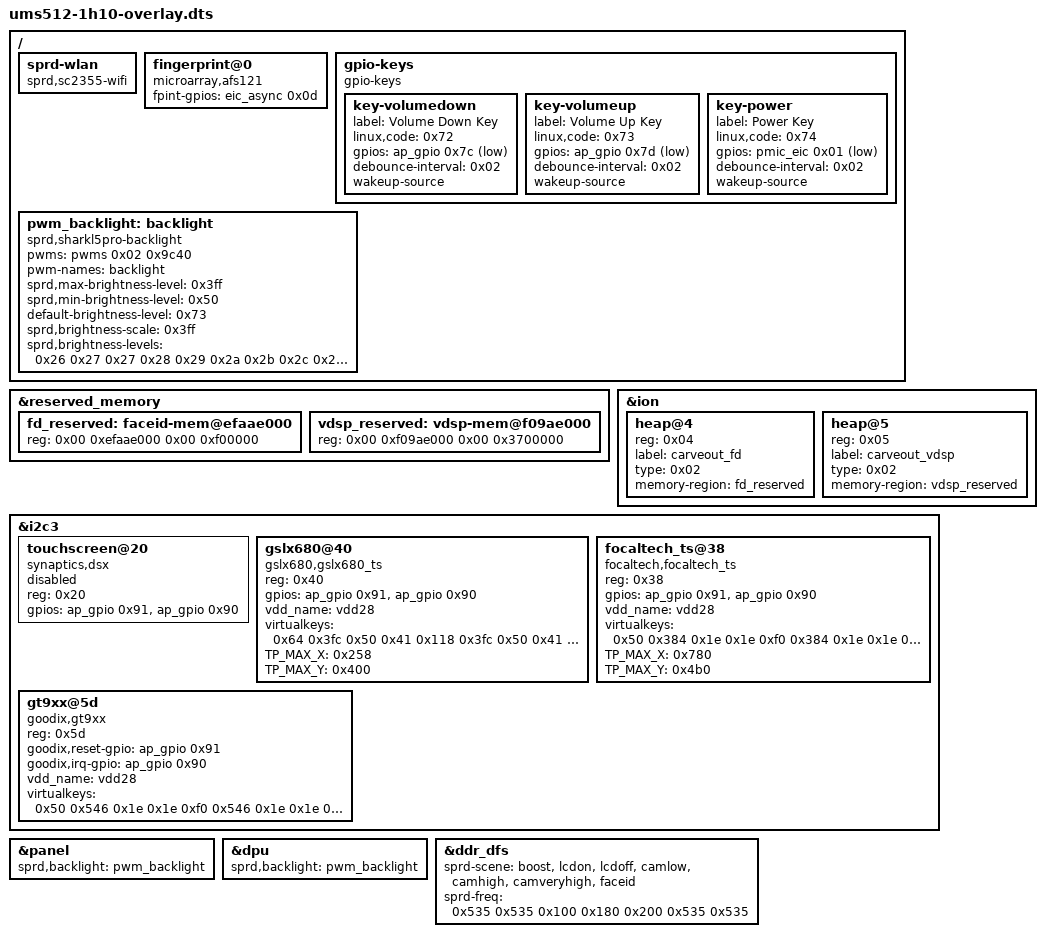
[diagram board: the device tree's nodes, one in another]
/dts-v1/;
/plugin/;

/ {
	fragment {
		target-path = "/";

		__overlay__ {
			sprd-wlan {
				compatible = "sprd,sc2355-wifi";
			};

			fingerprint@0 {
				compatible = "microarray,afs121";
				fpint-gpios = <&eic_async 0x0d 0x00>;
			};

			gpio-keys {
				compatible = "gpio-keys";

				key-volumedown {
					label = "Volume Down Key";
					linux,code = <0x72>;
					gpios = <&ap_gpio 0x7c 0x01>;
					debounce-interval = <0x02>;
					wakeup-source;
				};

				key-volumeup {
					label = "Volume Up Key";
					linux,code = <0x73>;
					gpios = <&ap_gpio 0x7d 0x01>;
					debounce-interval = <0x02>;
					wakeup-source;
				};

				key-power {
					label = "Power Key";
					linux,code = <0x74>;
					gpios = <&pmic_eic 0x01 0x01>;
					debounce-interval = <0x02>;
					wakeup-source;
				};
			};

			pwm_backlight: backlight {
				compatible = "sprd,sharkl5pro-backlight";
				pwms = <&pwms 0x02 0x9c40>;
				pwm-names = "backlight";
				sprd,max-brightness-level = <0x3ff>;
				sprd,min-brightness-level = <0x50>;
				default-brightness-level = <0x73>;
				sprd,brightness-scale = <0x3ff>;
				sprd,brightness-levels = <0x26 0x27 0x27 0x28 0x29 0x2a 0x2b 0x2c 0x2c 0x2d 0x2e 0x2f 0x30 0x31 0x31 0x32 0x33 0x34 0x35 0x36 0x36 0x37 0x38 0x39 0x3a 0x3b 0x3b 0x3c 0x3d 0x3e 0x3f 0x40 0x40 0x41 0x42 0x43 0x44 0x45 0x45 0x46 0x47 0x48 0x49 0x4a 0x4a 0x4b 0x4c 0x4d 0x4e 0x4f 0x4f 0x50 0x51 0x52 0x53 0x54 0x54 0x55 0x56 0x57 0x58 0x59 0x59 0x5a 0x5b 0x5c 0x5d 0x5e 0x5e 0x5f 0x60 0x61 0x62 0x63 0x64 0x64 0x65 0x66 0x67 0x68 0x69 0x6a 0x6a 0x6b 0x6c 0x6d 0x6e 0x6f 0x70 0x70 0x71 0x72 0x73 0x74 0x75 0x76 0x76 0x77 0x78 0x79 0x7a 0x7b 0x7c 0x7c 0x7d 0x7e 0x7f 0x80 0x81 0x82 0x82 0x83 0x84 0x85 0x86 0x87 0x88 0x88 0x89 0x8a 0x8b 0x8c 0x8d 0x8e 0x8e 0x8f 0x90 0x91 0x92 0x93 0x94 0x94 0x95 0x96 0x97 0x98 0x99 0x9a 0x9a 0x9b 0x9c 0x9d 0x9e 0x9f 0xa0 0xa0 0xa1 0xa2 0xa3 0xa4 0xa5 0xa6 0xa6 0xa7 0xa8 0xa9 0xaa 0xab 0xac 0xac 0xad 0xae 0xaf 0xb0 0xb1 0xb2 0xb2 0xb3 0xb4 0xb5 0xb6 0xb7 0xb8 0xb8 0xb9 0xba 0xbb 0xbc 0xbd 0xbe 0xbe 0xbf 0xc0 0xc1 0xc2 0xc3 0xc4 0xc4 0xc5 0xc6 0xc7 0xc8 0xc9 0xca 0xca 0xcb 0xcc 0xcd 0xce 0xcf 0xd0 0xd0 0xd1 0xd2 0xd3 0xd4 0xd5 0xd6 0xd6 0xd7 0xd8 0xd9 0xda 0xdb 0xdc 0xdc 0xdd 0xde 0xdf 0xe0 0xe1 0xe2 0xe2 0xe3 0xe4 0xe5 0xe6 0xe7 0xe8 0xe8 0xe9 0xea 0xeb 0xec 0xed 0xee 0xee 0xef 0xf0 0xf1 0xf2 0xf3 0xf4 0xf4 0xf5 0xf6 0xf7 0xf8 0xf9 0xfa 0xfa 0xfb 0xfc 0xfd 0xfe 0xff>;
			};
		};
	};

	fragment@0 {
		target = <&reserved_memory>;

		__overlay__ {
			fd_reserved: faceid-mem@efaae000 {
				reg = <0x00 0xefaae000 0x00 0xf00000>;
			};

			vdsp_reserved: vdsp-mem@f09ae000 {
				reg = <0x00 0xf09ae000 0x00 0x3700000>;
			};
		};
	};

	fragment@1 {
		target = <&ion>;

		__overlay__ {
			heap@4 {
				reg = <0x04>;
				label = "carveout_fd";
				type = <0x02>;
				memory-region = <&fd_reserved>;
			};

			heap@5 {
				reg = <0x05>;
				label = "carveout_vdsp";
				type = <0x02>;
				memory-region = <&vdsp_reserved>;
			};
		};
	};

	fragment@2 {
		target = <&i2c3>;

		__overlay__ {
			status = "okay";

			touchscreen@20 {
				status = "disabled";
				compatible = "synaptics,dsx";
				reg = <0x20>;
				gpios = <&ap_gpio 0x91 0x00 &ap_gpio 0x90 0x00>;
			};

			gslx680@40 {
				compatible = "gslx680,gslx680_ts";
				reg = <0x40>;
				gpios = <&ap_gpio 0x91 0x00 &ap_gpio 0x90 0x00>;
				vdd_name = "vdd28";
				virtualkeys = <0x64 0x3fc 0x50 0x41 0x118 0x3fc 0x50 0x41 0x1d6 0x3fc 0x50 0x41>;
				TP_MAX_X = <0x258>;
				TP_MAX_Y = <0x400>;
			};

			focaltech_ts@38 {
				status = "okay";
				compatible = "focaltech,focaltech_ts";
				reg = <0x38>;
				gpios = <&ap_gpio 0x91 0x00 &ap_gpio 0x90 0x00>;
				vdd_name = "vdd28";
				virtualkeys = <0x50 0x384 0x1e 0x1e 0xf0 0x384 0x1e 0x1e 0x190 0x384 0x1e 0x1e>;
				TP_MAX_X = <0x780>;
				TP_MAX_Y = <0x4b0>;
			};

			gt9xx@5d {
				status = "okay";
				compatible = "goodix,gt9xx";
				reg = <0x5d>;
				goodix,reset-gpio = <&ap_gpio 0x91 0x00>;
				goodix,irq-gpio = <&ap_gpio 0x90 0x00>;
				vdd_name = "vdd28";
				virtualkeys = <0x50 0x546 0x1e 0x1e 0xf0 0x546 0x1e 0x1e 0x190 0x546 0x1e 0x1e>;
			};
		};
	};

	fragment@3 {
		target = <&panel>;

		__overlay__ {
			sprd,backlight = <&pwm_backlight>;
		};
	};

	fragment@4 {
		target = <&dpu>;

		__overlay__ {
			sprd,backlight = <&pwm_backlight>;
		};
	};

	fragment@5 {
		target = <&ddr_dfs>;

		__overlay__ {
			sprd-scene = "boost", "lcdon", "lcdoff", "camlow", "camhigh", "camveryhigh", "faceid";
			sprd-freq = <0x535 0x535 0x100 0x180 0x200 0x535 0x535>;
		};
	};
};
